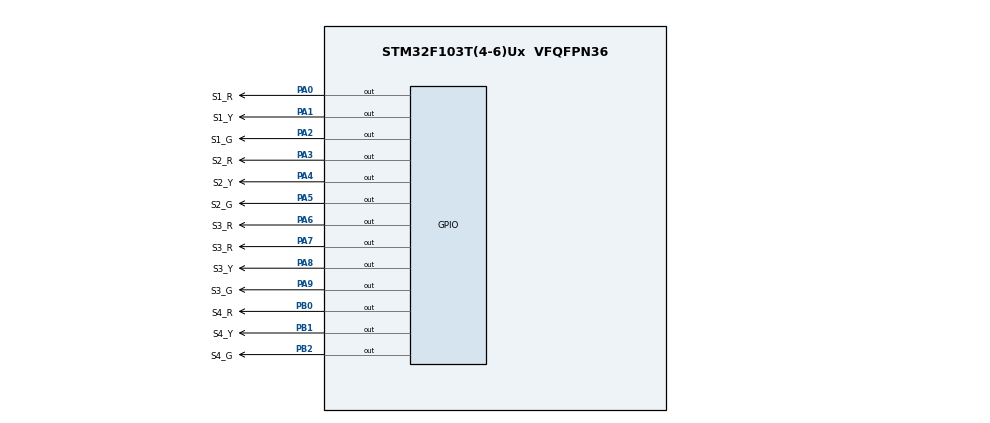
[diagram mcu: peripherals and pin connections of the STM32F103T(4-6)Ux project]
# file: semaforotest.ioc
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Mcu.Family=STM32F1
Mcu.Name=STM32F103T(4-6)Ux
Mcu.Package=VFQFPN36
NVIC.PriorityGroup=NVIC_PRIORITYGROUP_4
PA0-WKUP.GPIO_Label=S1_R
PA0-WKUP.Signal=GPIO_Output
PA1.GPIO_Label=S1_Y
PA1.Signal=GPIO_Output
PA2.GPIO_Label=S1_G
PA2.Signal=GPIO_Output
PA3.GPIO_Label=S2_R
PA3.Signal=GPIO_Output
PA4.GPIO_Label=S2_Y
PA4.Signal=GPIO_Output
PA5.GPIO_Label=S2_G
PA5.Signal=GPIO_Output
PA6.GPIO_Label=S3_R
PA6.Signal=GPIO_Output
PA7.GPIO_Label=S3_R
PA7.Signal=GPIO_Output
PA8.GPIO_Label=S3_Y
PA8.Signal=GPIO_Output
PA9.GPIO_Label=S3_G
PA9.Signal=GPIO_Output
PB0.GPIO_Label=S4_R
PB0.Signal=GPIO_Output
PB1.GPIO_Label=S4_Y
PB1.Signal=GPIO_Output
PB2.GPIO_Label=S4_G
PB2.Signal=GPIO_Output
ProjectManager.HeapSize=0x200
ProjectManager.StackSize=0x400
ProjectManager.TargetToolchain=STM32CubeIDE
RCC.APB1Freq_Value=8000000
RCC.APB2Freq_Value=8000000
VP_SYS_VS_ND.Mode=No_Debug
board=custom

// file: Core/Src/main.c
/* USER CODE BEGIN Header */
/**
  ******************************************************************************
  * @file           : main.c
  * @brief          : Main program body
  ******************************************************************************
  * @attention
  *
  * <h2><center>&copy; Copyright (c) 2022 STMicroelectronics.
  * All rights reserved.</center></h2>
  *
  * This software component is licensed by ST under BSD 3-Clause license,
  * the "License"; You may not use this file except in compliance with the
  * License. You may obtain a copy of the License at:
  *                        opensource.org/licenses/BSD-3-Clause
  *
  ******************************************************************************
  */
/* USER CODE END Header */

#include "main.h"

/* USER CODE BEGIN PTD */
typedef enum {ESTADO_1, ESTADO_2, ESTADO_3, ESTADO_4, ESTADO_5,
		ESTADO_6, ESTADO_7, ESTADO_8, ESTADO_9} Tipo_estado;

Tipo_estado estado_atual;

/* USER CODE END PTD */

void SystemClock_Config(void);
static void MX_GPIO_Init(void);

void EST_RST();
void EST_S1R();
void EST_S1Y();
void EST_S1G();
void EST_S2R();
void EST_S2Y();
void EST_S2G();
void EST_S3R();
void EST_S3Y();
void EST_S3G();
void EST_S4R();
void EST_S4Y();
void EST_S4G();
/* USER CODE BEGIN PFP */
void (*tabela_estados[])() = {&EST_RST, &EST_S1R, &EST_S1Y, &EST_S1G, &EST_S2R, &EST_S2Y,
		&EST_S2G, &EST_S3R, &EST_S3Y, &EST_S3G, &EST_S4R, &EST_S4Y, &EST_S4G};

/* USER CODE END PFP */

int main(void)
{

  /* MCU Configuration--------------------------------------------------------*/

  /* Reset of all peripherals, Initializes the Flash interface and the Systick. */
  HAL_Init();

  /* Configure the system clock */
  SystemClock_Config();

  /* Initialize all configured peripherals */
  MX_GPIO_Init();

  /* Infinite loop */
  while (1)
  {
	  tabela_estados[estado_atual]();
	  HAL_Delay(500);

  }
}

void SystemClock_Config(void)
{
  RCC_OscInitTypeDef RCC_OscInitStruct = {0};
  RCC_ClkInitTypeDef RCC_ClkInitStruct = {0};

  /** Initializes the CPU, AHB and APB busses clocks
  */
  RCC_OscInitStruct.OscillatorType = RCC_OSCILLATORTYPE_HSI;
  RCC_OscInitStruct.HSIState = RCC_HSI_ON;
  RCC_OscInitStruct.HSICalibrationValue = RCC_HSICALIBRATION_DEFAULT;
  RCC_OscInitStruct.PLL.PLLState = RCC_PLL_NONE;
  if (HAL_RCC_OscConfig(&RCC_OscInitStruct) != HAL_OK)
  {
    Error_Handler();
  }
  /** Initializes the CPU, AHB and APB busses clocks
  */
  RCC_ClkInitStruct.ClockType = RCC_CLOCKTYPE_HCLK|RCC_CLOCKTYPE_SYSCLK
                              |RCC_CLOCKTYPE_PCLK1|RCC_CLOCKTYPE_PCLK2;
  RCC_ClkInitStruct.SYSCLKSource = RCC_SYSCLKSOURCE_HSI;
  RCC_ClkInitStruct.AHBCLKDivider = RCC_SYSCLK_DIV1;
  RCC_ClkInitStruct.APB1CLKDivider = RCC_HCLK_DIV1;
  RCC_ClkInitStruct.APB2CLKDivider = RCC_HCLK_DIV1;

  if (HAL_RCC_ClockConfig(&RCC_ClkInitStruct, FLASH_LATENCY_0) != HAL_OK)
  {
    Error_Handler();
  }
}

static void MX_GPIO_Init(void)
{
  GPIO_InitTypeDef GPIO_InitStruct = {0};

  /* GPIO Ports Clock Enable */
  __HAL_RCC_GPIOA_CLK_ENABLE();
  __HAL_RCC_GPIOB_CLK_ENABLE();

  /*Configure GPIO pin Output Level */
  HAL_GPIO_WritePin(GPIOA, S1_R_Pin|S1_Y_Pin|S1_G_Pin|S2_R_Pin
                          |S2_Y_Pin|S2_G_Pin|S3_R_Pin|S3_RA7_Pin
                          |S3_Y_Pin|S3_G_Pin, GPIO_PIN_RESET);

  /*Configure GPIO pin Output Level */
  HAL_GPIO_WritePin(GPIOB, S4_R_Pin|S4_Y_Pin|S4_G_Pin, GPIO_PIN_RESET);

  /*Configure GPIO pins : S1_R_Pin S1_Y_Pin S1_G_Pin S2_R_Pin
                           S2_Y_Pin S2_G_Pin S3_R_Pin S3_RA7_Pin
                           S3_Y_Pin S3_G_Pin */
  GPIO_InitStruct.Pin = S1_R_Pin|S1_Y_Pin|S1_G_Pin|S2_R_Pin
                          |S2_Y_Pin|S2_G_Pin|S3_R_Pin|S3_RA7_Pin
                          |S3_Y_Pin|S3_G_Pin;
  GPIO_InitStruct.Mode = GPIO_MODE_OUTPUT_PP;
  GPIO_InitStruct.Pull = GPIO_NOPULL;
  GPIO_InitStruct.Speed = GPIO_SPEED_FREQ_LOW;
  HAL_GPIO_Init(GPIOA, &GPIO_InitStruct);

  /*Configure GPIO pins : S4_R_Pin S4_Y_Pin S4_G_Pin */
  GPIO_InitStruct.Pin = S4_R_Pin|S4_Y_Pin|S4_G_Pin;
  GPIO_InitStruct.Mode = GPIO_MODE_OUTPUT_PP;
  GPIO_InitStruct.Pull = GPIO_NOPULL;
  GPIO_InitStruct.Speed = GPIO_SPEED_FREQ_LOW;
  HAL_GPIO_Init(GPIOB, &GPIO_InitStruct);

}

/* USER CODE BEGIN 4 */
void EST_RST()
{

	HAL_GPIO_WritePin(S1_R_GPIO_Port,S1_R_Pin, 1);
	//HAL_GPIO_WritePin(S1_Y_GPIO_Port,S1_R_Pin, 0);
	//HAL_GPIO_WritePin(S1_G_GPIO_Port,S1_R_Pin, 0);

	//HAL_GPIO_WritePin(S2_R_GPIO_Port,S2_R_Pin, 1);
	//HAL_GPIO_WritePin(S2_Y_GPIO_Port,S2_R_Pin, 0);
	//HAL_GPIO_WritePin(S2_G_GPIO_Port,S2_R_Pin, 0);

	//HAL_GPIO_WritePin(S3_R_GPIO_Port,S3_R_Pin, 1);
	//HAL_GPIO_WritePin(S3_Y_GPIO_Port,S3_R_Pin, 0);
	//HAL_GPIO_WritePin(S3_G_GPIO_Port,S3_R_Pin, 0);

	//HAL_GPIO_WritePin(S4_R_GPIO_Port,S4_R_Pin, 1);
	//HAL_GPIO_WritePin(S4_Y_GPIO_Port,S4_R_Pin, 0);
	//HAL_GPIO_WritePin(S4_G_GPIO_Port,S4_R_Pin, 0);

}

/* USER CODE END 4 */

void Error_Handler(void)
{
}

/************************ (C) COPYRIGHT STMicroelectronics *****END OF FILE****/
